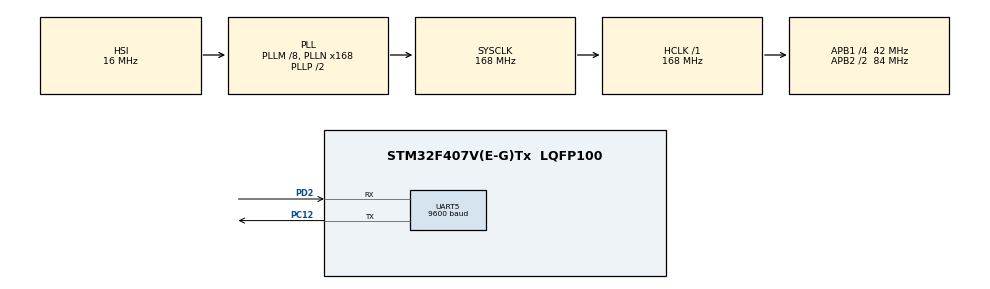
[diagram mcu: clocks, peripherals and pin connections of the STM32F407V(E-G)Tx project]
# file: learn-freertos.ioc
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FREERTOS.Tasks01=defaultTask,24,128,StartDefaultTask,Default,NULL,Dynamic,NULL,NULL
FREERTOS.configUSE_NEWLIB_REENTRANT=1
Mcu.Family=STM32F4
Mcu.Name=STM32F407V(E-G)Tx
Mcu.Package=LQFP100
NVIC.PriorityGroup=NVIC_PRIORITYGROUP_4
NVIC.TIM6_DAC_IRQn=true\:15\:0\:false\:false\:true\:false\:false\:true\:true
NVIC.TimeBase=TIM6_DAC_IRQn
NVIC.TimeBaseIP=TIM6
PC12.Mode=Asynchronous
PC12.Signal=UART5_TX
PD2.Mode=Asynchronous
PD2.Signal=UART5_RX
ProjectManager.HeapSize=0x200
ProjectManager.StackSize=0x400
ProjectManager.TargetToolchain=STM32CubeIDE
RCC.48MHZClocksFreq_Value=84000000
RCC.AHBFreq_Value=168000000
RCC.APB1CLKDivider=RCC_HCLK_DIV4
RCC.APB1Freq_Value=42000000
RCC.APB1TimFreq_Value=84000000
RCC.APB2CLKDivider=RCC_HCLK_DIV2
RCC.APB2Freq_Value=84000000
RCC.APB2TimFreq_Value=168000000
RCC.CortexFreq_Value=168000000
RCC.HCLKFreq_Value=168000000
RCC.HSE_VALUE=25000000
RCC.HSI_VALUE=16000000
RCC.LSE_VALUE=32768
RCC.PLLM=8
RCC.PLLN=168
RCC.SYSCLKFreq_VALUE=168000000
RCC.SYSCLKSource=RCC_SYSCLKSOURCE_PLLCLK
RCC.VCOOutputFreq_Value=336000000
UART5.BaudRate=9600
UART5.VirtualMode=Asynchronous
VP_FREERTOS_VS_CMSIS_V2.Mode=CMSIS_V2
VP_SYS_VS_tim6.Mode=TIM6
board=custom

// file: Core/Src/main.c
/* USER CODE BEGIN Header */
/**
 ******************************************************************************
 * @file           : main.c
 * @brief          : Main program body
 ******************************************************************************
 * @attention
 *
 * Copyright (c) 2026 STMicroelectronics.
 * All rights reserved.
 *
 * This software is licensed under terms that can be found in the LICENSE file
 * in the root directory of this software component.
 * If no LICENSE file comes with this software, it is provided AS-IS.
 *
 ******************************************************************************
 */
/* USER CODE END Header */
#include "main.h"
#include "cmsis_os.h"

/* USER CODE BEGIN Includes */
#include <stdio.h>
/* USER CODE END Includes */

/* USER CODE BEGIN PD */
#define mainDELAY_LOOP_COUNT 20000000
/* USER CODE END PD */

UART_HandleTypeDef huart5;

/* Definitions for defaultTask */
osThreadId_t defaultTaskHandle;
const osThreadAttr_t defaultTask_attributes = { .name = "defaultTask",
		.stack_size = 128 * 4, .priority = (osPriority_t) osPriorityNormal, };
/* USER CODE BEGIN PV */

int __io_putchar(int ch) {
	if (ch == '\n') {
		__io_putchar('\r');
	}

	HAL_UART_Transmit(&huart5, (uint8_t*) &ch, 1, HAL_MAX_DELAY);

	return 1;
}
/* USER CODE END PV */

void SystemClock_Config(void);
static void MX_GPIO_Init(void);
static void MX_UART5_Init(void);
void StartDefaultTask(void *argument);

/* USER CODE BEGIN 0 */
osMessageQueueId_t mojaKolejkaHandle;

void vTask1(void *argument) {

	for (;;) {
		int odbrana;
		osMessageQueueGet(mojaKolejkaHandle, &odbrana, NULL, osWaitForever);
		printf("%d \n", odbrana);
		osDelay(2000);
	}

}
void vTask3(void *argument);
void vTask2(void *pvParameters) {

	char *pcTaskName;
	pcTaskName = (char*) pvParameters;
	for (;;) {

		//printf("nie nie wazne\n");
		osDelay(1000);

	}
}
void vTask3(void *argument) {

	volatile unsigned long ulCount;
	for (ulCount = 0; ulCount < mainDELAY_LOOP_COUNT / 3; ulCount++) {

	}
	for (;;) {

		printf("task 3 here\n");

		for (ulCount = 0; ulCount < mainDELAY_LOOP_COUNT; ulCount++) {

		}

	}

}
/* USER CODE END 0 */

int main(void) {

	/* MCU Configuration--------------------------------------------------------*/

	/* Reset of all peripherals, Initializes the Flash interface and the Systick. */
	HAL_Init();

	/* Configure the system clock */
	SystemClock_Config();

	/* Initialize all configured peripherals */
	MX_GPIO_Init();
	MX_UART5_Init();

	/* Init scheduler */
	osKernelInitialize();

	/* Create the thread(s) */
	/* creation of defaultTask */
	defaultTaskHandle = osThreadNew(StartDefaultTask, NULL,
			&defaultTask_attributes);

	/* USER CODE BEGIN RTOS_THREADS */
	/* add threads, ... */
	static const char *pcTextFroTask2 = "takk 2";
	const osThreadAttr_t task1_attributes = { .name = "Task1", .stack_size = 128
			* 4, .priority = (osPriority_t) osPriorityNormal, };
	const osThreadAttr_t task2_attributes = { .name = "Task2", .stack_size = 128
			* 4, .priority = (osPriority_t) osPriorityNormal, };

	osThreadNew(vTask1, NULL, &task1_attributes);
	osThreadNew(vTask2, (void*) pcTextFroTask2, &task2_attributes);

		mojaKolejkaHandle =  osMessageQueueNew(10, sizeof(int), NULL);

	int elo = 10;
	osMessageQueuePut(mojaKolejkaHandle, &elo, 1, osWaitForever);
	elo = 123;
	osMessageQueuePut(mojaKolejkaHandle, &elo, 1, osWaitForever);
	elo = 88;
	osMessageQueuePut(mojaKolejkaHandle, &elo, 1, osWaitForever);

	/* USER CODE END RTOS_THREADS */

	/* Start scheduler */
	osKernelStart();

	/* We should never get here as control is now taken by the scheduler */

	/* Infinite loop */
	/* USER CODE BEGIN WHILE */
	vTaskStartScheduler();
	while (1) {
		/* USER CODE END WHILE */

	}
}

void SystemClock_Config(void) {
	RCC_OscInitTypeDef RCC_OscInitStruct = { 0 };
	RCC_ClkInitTypeDef RCC_ClkInitStruct = { 0 };

	/** Configure the main internal regulator output voltage
	 */
	__HAL_RCC_PWR_CLK_ENABLE();
	__HAL_PWR_VOLTAGESCALING_CONFIG(PWR_REGULATOR_VOLTAGE_SCALE1);

	/** Initializes the RCC Oscillators according to the specified parameters
	 * in the RCC_OscInitTypeDef structure.
	 */
	RCC_OscInitStruct.OscillatorType = RCC_OSCILLATORTYPE_HSI;
	RCC_OscInitStruct.HSIState = RCC_HSI_ON;
	RCC_OscInitStruct.HSICalibrationValue = RCC_HSICALIBRATION_DEFAULT;
	RCC_OscInitStruct.PLL.PLLState = RCC_PLL_ON;
	RCC_OscInitStruct.PLL.PLLSource = RCC_PLLSOURCE_HSI;
	RCC_OscInitStruct.PLL.PLLM = 8;
	RCC_OscInitStruct.PLL.PLLN = 168;
	RCC_OscInitStruct.PLL.PLLP = RCC_PLLP_DIV2;
	RCC_OscInitStruct.PLL.PLLQ = 4;
	if (HAL_RCC_OscConfig(&RCC_OscInitStruct) != HAL_OK) {
		Error_Handler();
	}

	/** Initializes the CPU, AHB and APB buses clocks
	 */
	RCC_ClkInitStruct.ClockType = RCC_CLOCKTYPE_HCLK | RCC_CLOCKTYPE_SYSCLK
			| RCC_CLOCKTYPE_PCLK1 | RCC_CLOCKTYPE_PCLK2;
	RCC_ClkInitStruct.SYSCLKSource = RCC_SYSCLKSOURCE_PLLCLK;
	RCC_ClkInitStruct.AHBCLKDivider = RCC_SYSCLK_DIV1;
	RCC_ClkInitStruct.APB1CLKDivider = RCC_HCLK_DIV4;
	RCC_ClkInitStruct.APB2CLKDivider = RCC_HCLK_DIV2;

	if (HAL_RCC_ClockConfig(&RCC_ClkInitStruct, FLASH_LATENCY_5) != HAL_OK) {
		Error_Handler();
	}
}

static void MX_UART5_Init(void) {

	huart5.Instance = UART5;
	huart5.Init.BaudRate = 9600;
	huart5.Init.WordLength = UART_WORDLENGTH_8B;
	huart5.Init.StopBits = UART_STOPBITS_1;
	huart5.Init.Parity = UART_PARITY_NONE;
	huart5.Init.Mode = UART_MODE_TX_RX;
	huart5.Init.HwFlowCtl = UART_HWCONTROL_NONE;
	huart5.Init.OverSampling = UART_OVERSAMPLING_16;
	if (HAL_UART_Init(&huart5) != HAL_OK) {
		Error_Handler();
	}

}

static void MX_GPIO_Init(void) {

	/* GPIO Ports Clock Enable */
	__HAL_RCC_GPIOC_CLK_ENABLE();
	__HAL_RCC_GPIOD_CLK_ENABLE();

}

void StartDefaultTask(void *argument) {
	for (;;) {
		osDelay(1);
	}
}

void HAL_TIM_PeriodElapsedCallback(TIM_HandleTypeDef *htim) {
	if (htim->Instance == TIM6) {
		HAL_IncTick();
	}
}

void Error_Handler(void) {
	__disable_irq();
	while (1) {
	}
}
